# HC32A4A8RITJ register map
File version: 1.0
CPU: CM4 r0p1, little endian, MPU, FPU, 4 interrupt priority bits
Registers are 32-bit, read-write, reset 0x0 unless marked. A register's access mark holds for its fields unless they carry their own. Offsets are from the block's base; [hi:lo] are bit positions; 'fields as' and 'values as' point back to an identical list.

## TMR21 — desc TMR2
Base 0x40024800
Same registers: TMR22 0x40024C00, TMR23 0x40025000, TMR24 0x40025400
0x00 CNTAR
  [15:0] CNTA
0x04 CNTBR
  [15:0] CNTB
0x08 CMPAR reset 0xFFFF
  [15:0] CMPA
0x0C CMPBR reset 0xFFFF
  [15:0] CMPB
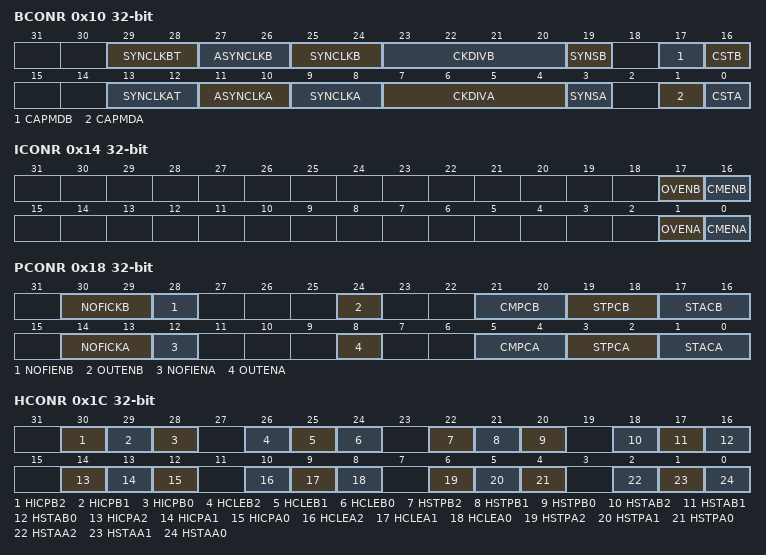
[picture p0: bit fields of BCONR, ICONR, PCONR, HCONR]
0x10 BCONR
  [29:28] SYNCLKBT, [27:26] ASYNCLKB, [25:24] SYNCLKB, [23:20] CKDIVB, [19] SYNSB, [17] CAPMDB, [16] CSTB, [13:12] SYNCLKAT, [11:10] ASYNCLKA, [9:8] SYNCLKA, [7:4] CKDIVA, [3] SYNSA, [1] CAPMDA, [0] CSTA
0x14 ICONR
  [17] OVENB, [16] CMENB, [1] OVENA, [0] CMENA
0x18 PCONR
  [30:29] NOFICKB, [28] NOFIENB, [24] OUTENB, [21:20] CMPCB, [19:18] STPCB, [17:16] STACB, [14:13] NOFICKA, [12] NOFIENA, [8] OUTENA, [5:4] CMPCA, [3:2] STPCA, [1:0] STACA
0x1C HCONR
  [30] HICPB2, [29] HICPB1, [28] HICPB0, [26] HCLEB2, [25] HCLEB1, [24] HCLEB0, [22] HSTPB2, [21] HSTPB1, [20] HSTPB0, [18] HSTAB2, [17] HSTAB1, [16] HSTAB0, [14] HICPA2, [13] HICPA1, [12] HICPA0, [10] HCLEA2, [9] HCLEA1, [8] HCLEA0, [6] HSTPA2, [5] HSTPA1, [4] HSTPA0, [2] HSTAA2, [1] HSTAA1, [0] HSTAA0
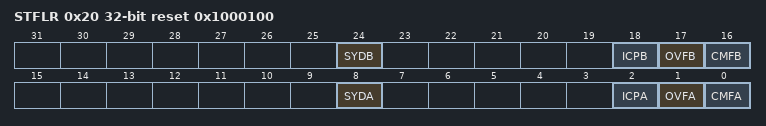
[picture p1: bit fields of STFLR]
0x20 STFLR reset 0x1000100
  [24] SYDB, [18] ICPB, [17] OVFB, [16] CMFB, [8] SYDA, [2] ICPA, [1] OVFA, [0] CMFA

## TMR41 — desc TMR4
Base 0x40038000
0x02 OCCRUH 16-bit
0x06 OCCRUL 16-bit
0x0A OCCRVH 16-bit
0x0E OCCRVL 16-bit
0x12 OCCRWH 16-bit
0x16 OCCRWL 16-bit
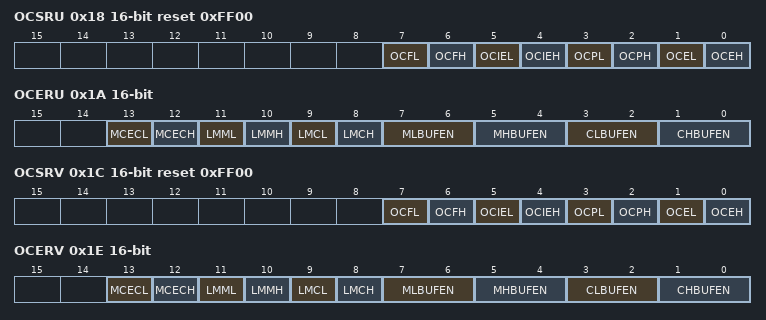
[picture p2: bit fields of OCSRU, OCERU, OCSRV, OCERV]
0x18 OCSRU 16-bit reset 0xFF00
  [7] OCFL, [6] OCFH, [5] OCIEL, [4] OCIEH, [3] OCPL, [2] OCPH, [1] OCEL, [0] OCEH
0x1A OCERU 16-bit
  [13] MCECL, [12] MCECH, [11] LMML, [10] LMMH, [9] LMCL, [8] LMCH, [7:6] MLBUFEN, [5:4] MHBUFEN, [3:2] CLBUFEN, [1:0] CHBUFEN
0x1C OCSRV 16-bit reset 0xFF00
  fields as OCSRU
0x1E OCERV 16-bit
  fields as OCERU
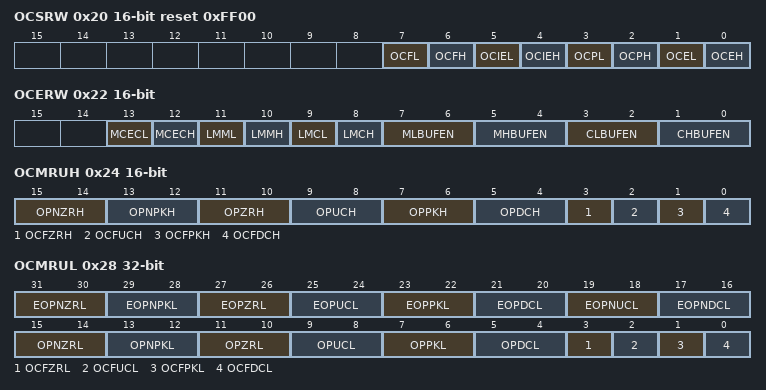
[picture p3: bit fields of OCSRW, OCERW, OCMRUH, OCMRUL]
0x20 OCSRW 16-bit reset 0xFF00
  fields as OCSRU
0x22 OCERW 16-bit
  fields as OCERU
0x24 OCMRUH 16-bit
  [15:14] OPNZRH, [13:12] OPNPKH, [11:10] OPZRH, [9:8] OPUCH, [7:6] OPPKH, [5:4] OPDCH, [3] OCFZRH, [2] OCFUCH, [1] OCFPKH, [0] OCFDCH
0x28 OCMRUL
  [31:30] EOPNZRL, [29:28] EOPNPKL, [27:26] EOPZRL, [25:24] EOPUCL, [23:22] EOPPKL, [21:20] EOPDCL, [19:18] EOPNUCL, [17:16] EOPNDCL, [15:14] OPNZRL, [13:12] OPNPKL, [11:10] OPZRL, [9:8] OPUCL, [7:6] OPPKL, [5:4] OPDCL, [3] OCFZRL, [2] OCFUCL, [1] OCFPKL, [0] OCFDCL
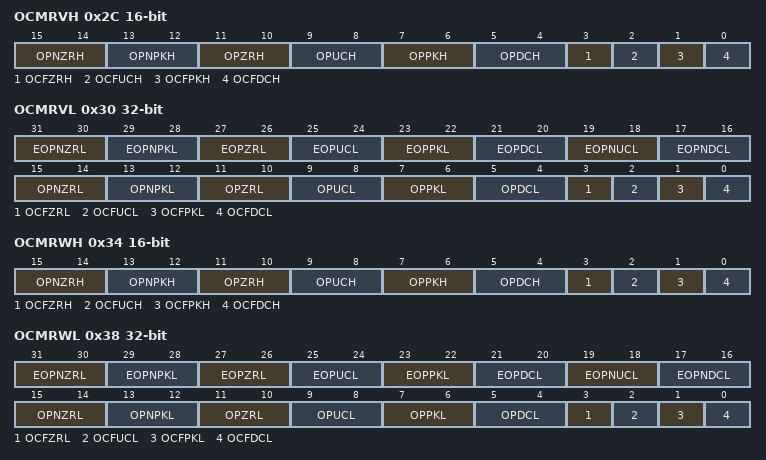
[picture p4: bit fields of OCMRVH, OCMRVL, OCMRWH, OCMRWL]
0x2C OCMRVH 16-bit
  fields as OCMRUH
0x30 OCMRVL
  fields as OCMRUL
0x34 OCMRWH 16-bit
  fields as OCMRUH
0x38 OCMRWL
  fields as OCMRUL
0x42 CPSR 16-bit reset 0xFFFF
0x46 CNTR 16-bit
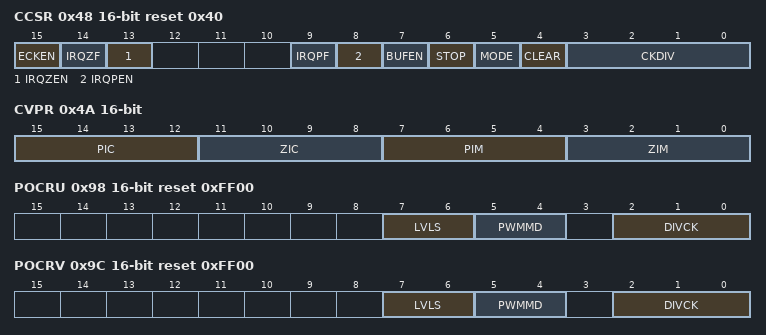
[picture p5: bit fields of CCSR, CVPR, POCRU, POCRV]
0x48 CCSR 16-bit reset 0x40
  [15] ECKEN, [14] IRQZF, [13] IRQZEN, [9] IRQPF, [8] IRQPEN, [7] BUFEN, [6] STOP, [5] MODE, [4] CLEAR, [3:0] CKDIV
0x4A CVPR 16-bit
  [15:12] PIC ro, [11:8] ZIC ro, [7:4] PIM, [3:0] ZIM
0x82 PFSRU 16-bit
0x84 PDARU 16-bit
0x86 PDBRU 16-bit
0x8A PFSRV 16-bit
0x8C PDARV 16-bit
0x8E PDBRV 16-bit
0x92 PFSRW 16-bit
0x94 PDARW 16-bit
0x96 PDBRW 16-bit
0x98 POCRU 16-bit reset 0xFF00
  [7:6] LVLS, [5:4] PWMMD, [2:0] DIVCK
0x9C POCRV 16-bit reset 0xFF00
  [7:6] LVLS, [5:4] PWMMD, [2:0] DIVCK
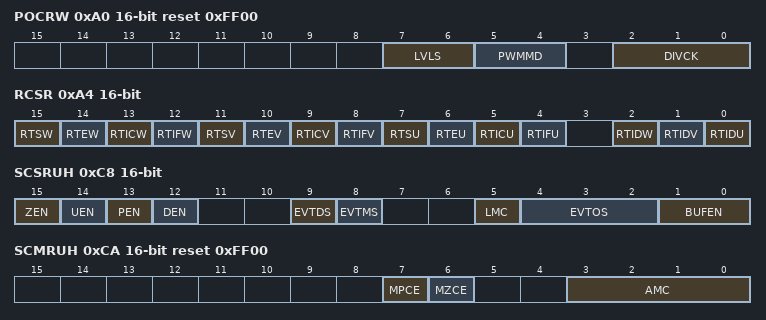
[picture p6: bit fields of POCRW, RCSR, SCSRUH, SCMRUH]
0xA0 POCRW 16-bit reset 0xFF00
  [7:6] LVLS, [5:4] PWMMD, [2:0] DIVCK
0xA4 RCSR 16-bit
  [15] RTSW, [14] RTEW, [13] RTICW, [12] RTIFW ro, [11] RTSV, [10] RTEV, [9] RTICV, [8] RTIFV ro, [7] RTSU, [6] RTEU, [5] RTICU, [4] RTIFU ro, [2] RTIDW, [1] RTIDV, [0] RTIDU
0xB2 SCCRUH 16-bit
0xB6 SCCRUL 16-bit
0xBA SCCRVH 16-bit
0xBE SCCRVL 16-bit
0xC2 SCCRWH 16-bit
0xC6 SCCRWL 16-bit
0xC8 SCSRUH 16-bit
  [15] ZEN, [14] UEN, [13] PEN, [12] DEN, [9] EVTDS, [8] EVTMS, [5] LMC, [4:2] EVTOS, [1:0] BUFEN
0xCA SCMRUH 16-bit reset 0xFF00
  [7] MPCE, [6] MZCE, [3:0] AMC
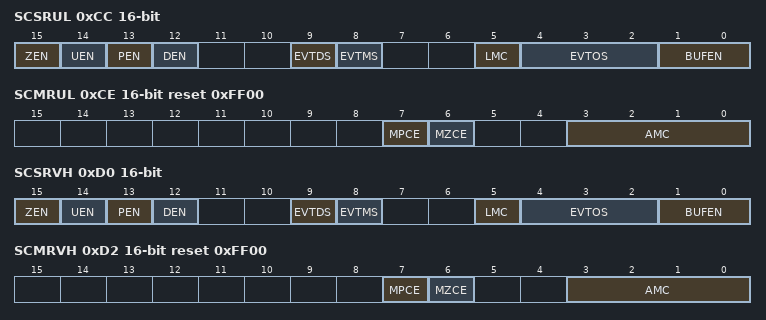
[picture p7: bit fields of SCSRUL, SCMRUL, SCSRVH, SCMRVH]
0xCC SCSRUL 16-bit
  fields as SCSRUH
0xCE SCMRUL 16-bit reset 0xFF00
  [7] MPCE, [6] MZCE, [3:0] AMC
0xD0 SCSRVH 16-bit
  fields as SCSRUH
0xD2 SCMRVH 16-bit reset 0xFF00
  [7] MPCE, [6] MZCE, [3:0] AMC
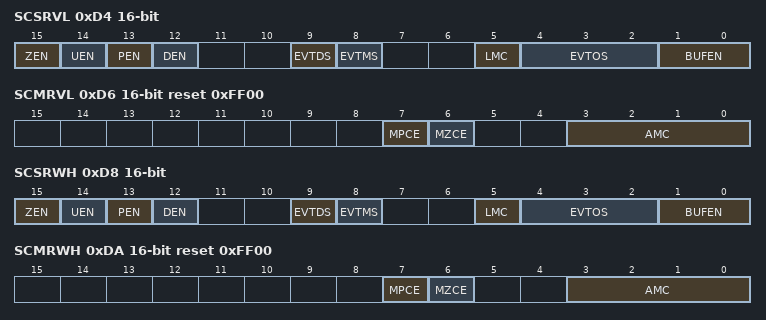
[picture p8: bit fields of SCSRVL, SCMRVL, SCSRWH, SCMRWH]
0xD4 SCSRVL 16-bit
  fields as SCSRUH
0xD6 SCMRVL 16-bit reset 0xFF00
  [7] MPCE, [6] MZCE, [3:0] AMC
0xD8 SCSRWH 16-bit
  fields as SCSRUH
0xDA SCMRWH 16-bit reset 0xFF00
  [7] MPCE, [6] MZCE, [3:0] AMC
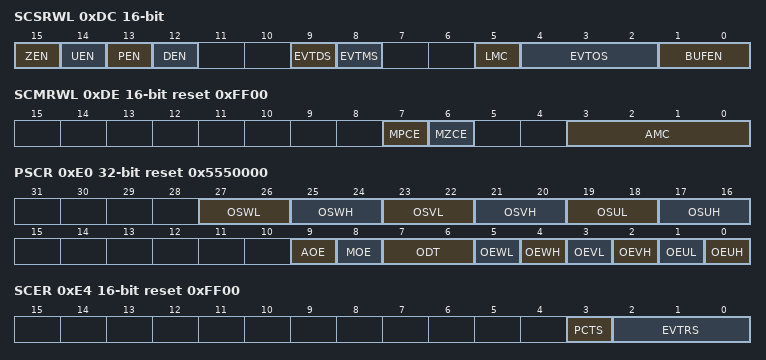
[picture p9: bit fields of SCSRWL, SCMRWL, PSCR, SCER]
0xDC SCSRWL 16-bit
  fields as SCSRUH
0xDE SCMRWL 16-bit reset 0xFF00
  [7] MPCE, [6] MZCE, [3:0] AMC
0xE0 PSCR reset 0x5550000
  [27:26] OSWL, [25:24] OSWH, [23:22] OSVL, [21:20] OSVH, [19:18] OSUL, [17:16] OSUH, [9] AOE, [8] MOE, [7:6] ODT, [5] OEWL, [4] OEWH, [3] OEVL, [2] OEVH, [1] OEUL, [0] OEUH
0xE4 SCER 16-bit reset 0xFF00
  [3] PCTS, [2:0] EVTRS

## TMR42 — desc TMR4
Base 0x40038400
Same registers: TMR43 0x40038800
Registers as TMR41; these are added or differ:
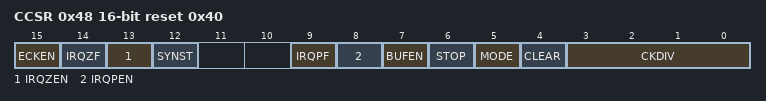
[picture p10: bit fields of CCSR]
0x48 CCSR 16-bit reset 0x40
  [15] ECKEN, [14] IRQZF, [13] IRQZEN, [12] SYNST, [9] IRQPF, [8] IRQPEN, [7] BUFEN, [6] STOP, [5] MODE, [4] CLEAR, [3:0] CKDIV
